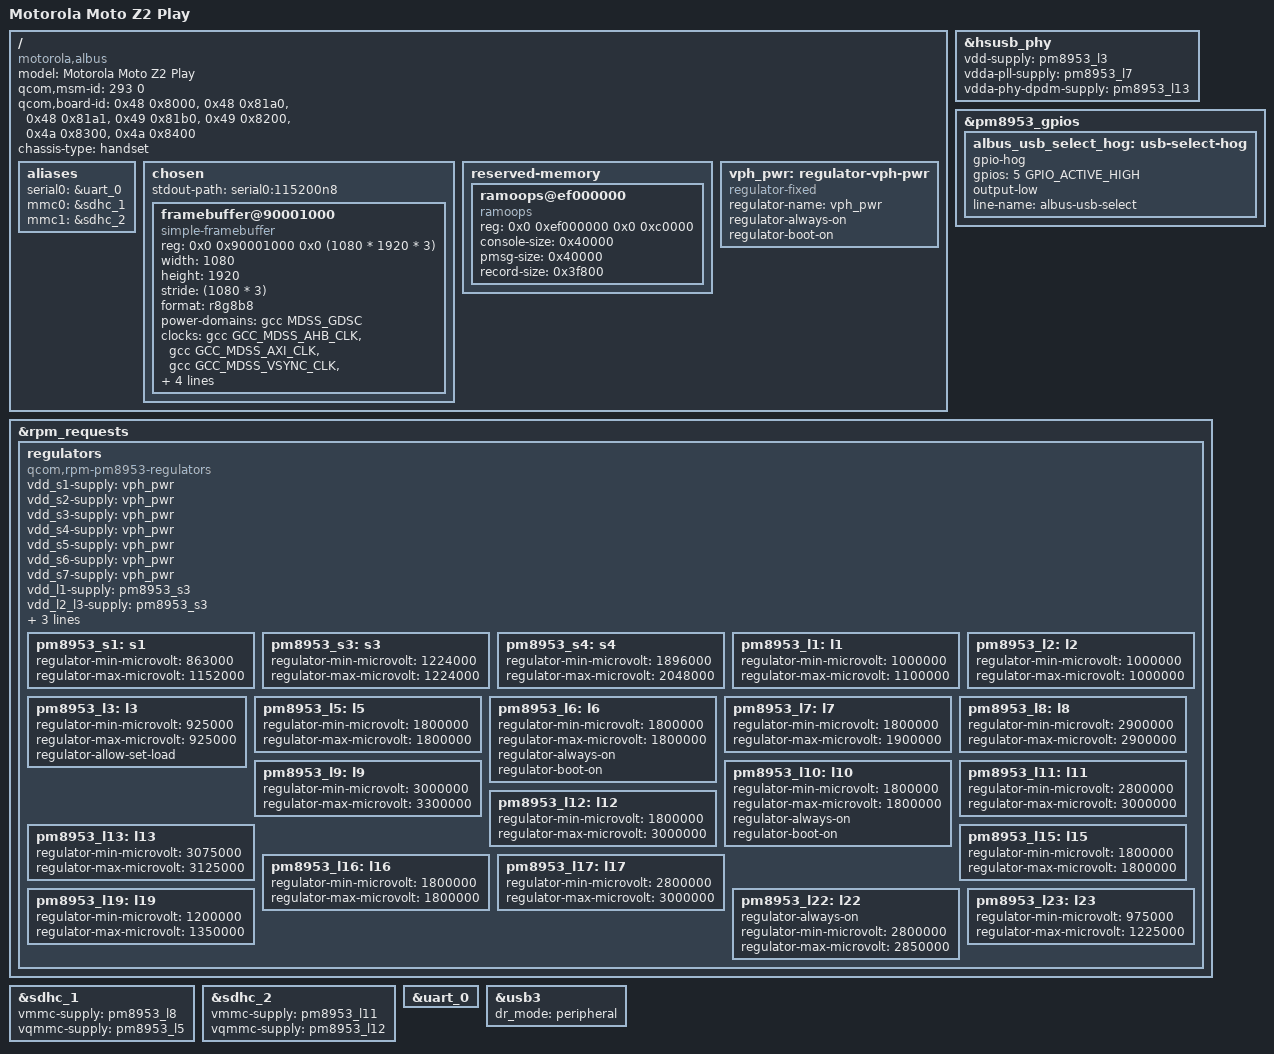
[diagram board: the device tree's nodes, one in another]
// SPDX-License-Identifier: BSD-3-Clause
/*
 * Motorola Moto Z2 Play (albus), initial mainline device tree.
 *
 * Device identification, SoC and boot image parameters:
 *   LineageOS/android_device_motorola_albus, BoardConfig.mk
 *
 * The PM8953 regulator topology and MSM8953 controller definitions come
 * from the existing Motorola MSM8953 device trees in this kernel.
 * Albus-specific USB selection (FSUSB42) and ramoops reservation are based
 * on Alberto97/android_kernel_motorola_msm8953, pie:
 * arch/arm/boot/dts/qcom/msm8953-{moto-common,albus}.dtsi.
 * The FUSB302 Type-C controller and HD3SS460 switch are not enabled until
 * their VBUS supply and routing can be modeled with mainline bindings.
 * Keep this file board-local: Channel/Deen/Sanders use different hardware.
 * Stock Motorola's separate QCDT boot images use MSM8953 ID 293 and the
 * seven Albus platform/subtype IDs from downstream msm8953-albus-p*.dts.
 * These IDs are Albus-only; no Sanders/Channel IDs belong here.
 */
/dts-v1/;

#include "msm8953.dtsi"
#include "pm8953.dtsi"
#include "pmi8950.dtsi"

/ {
	model = "Motorola Moto Z2 Play";
	compatible = "motorola,albus", "qcom,msm8953";
	/* Qualcomm LK DTB matching for Albus p0, p1, p1a1, p1b, p2, p3, p4. */
	qcom,msm-id = <293 0>;
	qcom,board-id = <0x48 0x8000>,
			<0x48 0x81a0>,
			<0x48 0x81a1>,
			<0x49 0x81b0>,
			<0x49 0x8200>,
			<0x4a 0x8300>,
			<0x4a 0x8400>;
	chassis-type = "handset";

	aliases {
		serial0 = &uart_0;
		mmc0 = &sdhc_1;
		mmc1 = &sdhc_2;
	};

	chosen {
		#address-cells = <2>;
		#size-cells = <2>;
		ranges;

		stdout-path = "serial0:115200n8";

		/*
		 * Reuse the continuous-splash framebuffer until an Albus DSI
		 * panel driver is available. The stock/lk2nd Albus panel is
		 * 1080x1920 RGB888; msm8953.dtsi reserves the 0x90001000
		 * splash region. This follows the framebuffer approach in
		 * SDM632 Channel and MSM8953 Potter, without reusing their panels.
		 *
		 * The bootloader must have initialized the panel for pixels
		 * to remain visible. No guarantee for every Albus panel revision.
		 */
		framebuffer@90001000 {
			compatible = "simple-framebuffer";
			reg = <0x0 0x90001000 0x0 (1080 * 1920 * 3)>;
			width = <1080>;
			height = <1920>;
			stride = <(1080 * 3)>;
			format = "r8g8b8";

			power-domains = <&gcc MDSS_GDSC>;
			clocks = <&gcc GCC_MDSS_AHB_CLK>,
				 <&gcc GCC_MDSS_AXI_CLK>,
				 <&gcc GCC_MDSS_VSYNC_CLK>,
				 <&gcc GCC_MDSS_MDP_CLK>,
				 <&gcc GCC_MDSS_BYTE0_CLK>,
				 <&gcc GCC_MDSS_PCLK0_CLK>,
				 <&gcc GCC_MDSS_ESC0_CLK>;
		};
	};

	/*
	 * Stock Motorola MSM8953 reserves ef000000-ef0bffff for persistent
	 * crash logs. This stays local to Albus; it must not be copied to
	 * other boards without confirming their reserved-memory layout.
	 */
	reserved-memory {
		ramoops@ef000000 {
			compatible = "ramoops";
			reg = <0x0 0xef000000 0x0 0xc0000>;
			console-size = <0x40000>;
			pmsg-size = <0x40000>;
			record-size = <0x3f800>;
		};
	};

	vph_pwr: regulator-vph-pwr {
		compatible = "regulator-fixed";
		regulator-name = "vph_pwr";
		regulator-always-on;
		regulator-boot-on;
	};
};

&hsusb_phy {
	vdd-supply = <&pm8953_l3>;
	vdda-pll-supply = <&pm8953_l7>;
	vdda-phy-dpdm-supply = <&pm8953_l13>;
	status = "okay";
};

/*
 * The Albus FSUSB42 shares the external USB-C connector with Moto Mods.
 * Stock wiring: FSUSB42 selection is PM8953 GPIO6 (zero-based GPIO5).
 * Stock fsusb42_mux.c: FSUSB_STATE_USB drives selection LOW; HIGH
 * selects another path or powers the switch off.
 *
 * Keep the wired USB path connected to the application processor until
 * a fully modeled Type-C/USB-mux solution is available. This alone does
 * not implement FUSB302 power-role negotiation or the HD3SS460 switch.
 */
&pm8953_gpios {
	albus_usb_select_hog: usb-select-hog {
		gpio-hog;
		gpios = <5 GPIO_ACTIVE_HIGH>;
		output-low;
		line-name = "albus-usb-select";
	};
};

&rpm_requests {
	regulators {
		compatible = "qcom,rpm-pm8953-regulators";

		vdd_s1-supply = <&vph_pwr>;
		vdd_s2-supply = <&vph_pwr>;
		vdd_s3-supply = <&vph_pwr>;
		vdd_s4-supply = <&vph_pwr>;
		vdd_s5-supply = <&vph_pwr>;
		vdd_s6-supply = <&vph_pwr>;
		vdd_s7-supply = <&vph_pwr>;
		vdd_l1-supply = <&pm8953_s3>;
		vdd_l2_l3-supply = <&pm8953_s3>;
		vdd_l4_l5_l6_l7_l16_l19-supply = <&pm8953_s4>;
		vdd_l8_l11_l12_l13_l14_l15-supply = <&vph_pwr>;
		vdd_l9_l10_l17_l18_l22-supply = <&vph_pwr>;

		pm8953_s1: s1 {
			regulator-min-microvolt = <863000>;
			regulator-max-microvolt = <1152000>;
		};

		pm8953_s3: s3 {
			regulator-min-microvolt = <1224000>;
			regulator-max-microvolt = <1224000>;
		};

		pm8953_s4: s4 {
			regulator-min-microvolt = <1896000>;
			regulator-max-microvolt = <2048000>;
		};

		pm8953_l1: l1 {
			regulator-min-microvolt = <1000000>;
			regulator-max-microvolt = <1100000>;
		};

		pm8953_l2: l2 {
			regulator-min-microvolt = <1000000>;
			regulator-max-microvolt = <1000000>;
		};

		pm8953_l3: l3 {
			regulator-min-microvolt = <925000>;
			regulator-max-microvolt = <925000>;
			regulator-allow-set-load;
		};

		pm8953_l5: l5 {
			regulator-min-microvolt = <1800000>;
			regulator-max-microvolt = <1800000>;
		};

		pm8953_l6: l6 {
			regulator-min-microvolt = <1800000>;
			regulator-max-microvolt = <1800000>;
			regulator-always-on;
			regulator-boot-on;
		};

		pm8953_l7: l7 {
			regulator-min-microvolt = <1800000>;
			regulator-max-microvolt = <1900000>;
		};

		pm8953_l8: l8 {
			regulator-min-microvolt = <2900000>;
			regulator-max-microvolt = <2900000>;
		};

		pm8953_l9: l9 {
			regulator-min-microvolt = <3000000>;
			regulator-max-microvolt = <3300000>;
		};

		pm8953_l10: l10 {
			regulator-min-microvolt = <1800000>;
			regulator-max-microvolt = <1800000>;
			regulator-always-on;
			regulator-boot-on;
		};

		pm8953_l11: l11 {
			regulator-min-microvolt = <2800000>;
			regulator-max-microvolt = <3000000>;
		};

		pm8953_l12: l12 {
			regulator-min-microvolt = <1800000>;
			regulator-max-microvolt = <3000000>;
		};

		pm8953_l13: l13 {
			regulator-min-microvolt = <3075000>;
			regulator-max-microvolt = <3125000>;
		};

		pm8953_l15: l15 {
			regulator-min-microvolt = <1800000>;
			regulator-max-microvolt = <1800000>;
		};

		pm8953_l16: l16 {
			regulator-min-microvolt = <1800000>;
			regulator-max-microvolt = <1800000>;
		};

		pm8953_l17: l17 {
			regulator-min-microvolt = <2800000>;
			regulator-max-microvolt = <3000000>;
		};

		pm8953_l19: l19 {
			regulator-min-microvolt = <1200000>;
			regulator-max-microvolt = <1350000>;
		};

		pm8953_l22: l22 {
			regulator-always-on;
			regulator-min-microvolt = <2800000>;
			regulator-max-microvolt = <2850000>;
		};

		pm8953_l23: l23 {
			regulator-min-microvolt = <975000>;
			regulator-max-microvolt = <1225000>;
		};
	};
};

&sdhc_1 {
	vmmc-supply = <&pm8953_l8>;
	vqmmc-supply = <&pm8953_l5>;
	status = "okay";
};

&sdhc_2 {
	vmmc-supply = <&pm8953_l11>;
	vqmmc-supply = <&pm8953_l12>;
	status = "okay";
};

&uart_0 {
	status = "okay";
};

/* Until FUSB302/HD3SS460 are described, make the USB gadget mode
 * explicit rather than waiting for an unimplemented Type-C role switch.
 * This does not supply VBUS or initialize the physical Type-C mux.
 */
&usb3 {
	/delete-property/ usb-role-switch;
	/delete-property/ role-switch-default-mode;
	dr_mode = "peripheral";
	status = "okay";
};
